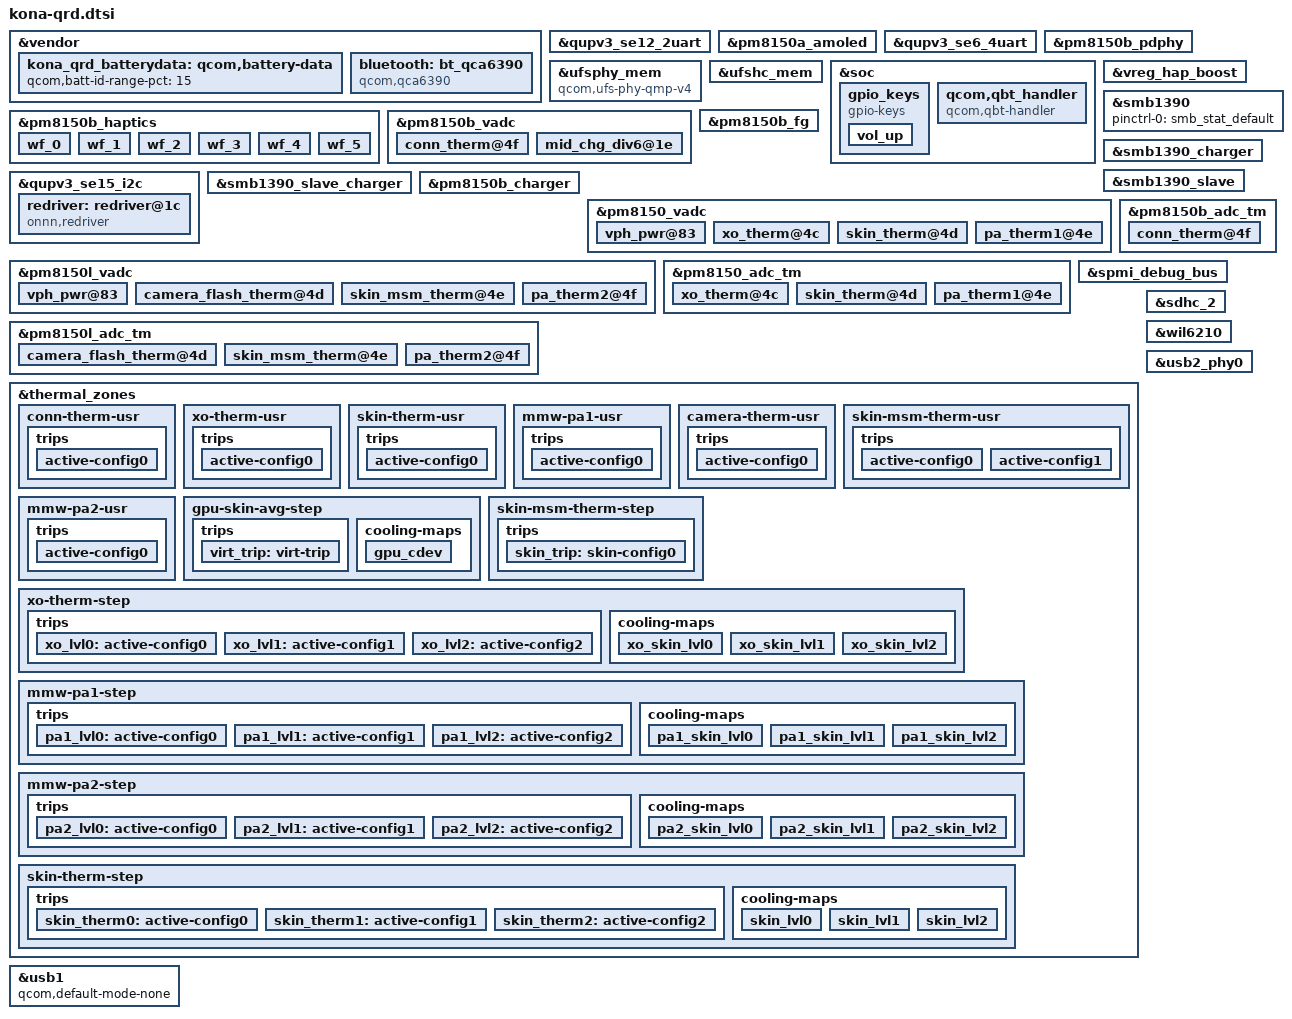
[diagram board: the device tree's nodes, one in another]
#include <dt-bindings/gpio/gpio.h>
#include "kona-pmic-overlay.dtsi"
#include "kona-thermal-overlay.dtsi"
#include "kona-audio-overlay.dtsi"
#include <dt-bindings/iio/qti_power_supply_iio.h>
#include "display/kona-sde.dtsi"
#include "display/kona-sde-display.dtsi"

&vendor {
	kona_qrd_batterydata: qcom,battery-data {
		qcom,batt-id-range-pct = <15>;
	};
};

&qupv3_se12_2uart {
	status = "okay";
};

&pm8150a_amoled {
	status = "ok";
};

&qupv3_se6_4uart {
	status = "ok";
};

&pm8150b_pdphy {
	#io-channel-cells = <1>;
	io-channels = <&pm8150b_charger PSY_IIO_PD_ACTIVE>,
		      <&pm8150b_charger PSY_IIO_TYPEC_CC_ORIENTATION>,
		      <&pm8150b_charger PSY_IIO_CONNECTOR_TYPE>,
		      <&pm8150b_charger PSY_IIO_TYPEC_POWER_ROLE>,
		      <&pm8150b_charger PSY_IIO_PD_USB_SUSPEND_SUPPORTED>,
		      <&pm8150b_charger PSY_IIO_TYPEC_SRC_RP>,
		      <&pm8150b_charger PSY_IIO_PD_IN_HARD_RESET>,
		      <&pm8150b_charger PSY_IIO_PD_CURRENT_MAX>,
		      <&pm8150b_charger PSY_IIO_PR_SWAP>,
		      <&pm8150b_charger PSY_IIO_PD_VOLTAGE_MIN>,
		      <&pm8150b_charger PSY_IIO_PD_VOLTAGE_MAX>,
		      <&pm8150b_charger PSY_IIO_USB_REAL_TYPE>,
		      <&pm8150b_charger PSY_IIO_TYPEC_MODE>,
		      <&pm8150b_charger PSY_IIO_PE_START>;
	io-channel-names = "pd_active",
			   "typec_cc_orientation",
			   "connector_type",
			   "typec_power_role",
			   "pd_usb_suspend_supported",
			   "typec_src_rp",
			   "pd_in_hard_reset",
			   "pr_current_max",
			   "pr_swap",
			   "pd_voltage_min",
			   "pd_voltage_max",
			   "real_type",
			   "typec_mode",
			   "pe_start";
};

&ufsphy_mem {
	compatible = "qcom,ufs-phy-qmp-v4";

	vdda-phy-supply = <&pm8150_l5>;
	vdda-phy-always-on;
	vdda-pll-supply = <&pm8150_l9>;
	vdda-phy-max-microamp = <89900>;
	vdda-pll-max-microamp = <18800>;

	status = "ok";
};

&ufshc_mem {
	limit-tx-hs-gear = <3>;
	limit-rx-hs-gear = <3>;
	limit-rate = <1>; /* HS Rate-A */
	vdd-hba-supply = <&ufs_phy_gdsc>;
	vdd-hba-fixed-regulator;
	vcc-supply = <&pm8150_l17>;
	vcc-voltage-level = <2504000 2950000>;
	vcc-low-voltage-sup;
	vccq-supply = <&pm8150_l6>;
	vccq2-supply = <&pm8150_s4>;
	vcc-max-microamp = <800000>;
	vccq-max-microamp = <800000>;
	vccq2-max-microamp = <800000>;

	qcom,vddp-ref-clk-supply = <&pm8150_l6>;
	qcom,vddp-ref-clk-max-microamp = <100>;
	qcom,vccq-parent-supply = <&pm8150a_s8>;
	qcom,vccq-parent-max-microamp = <210000>;

	status = "ok";
};

&soc {
	gpio_keys {
		compatible = "gpio-keys";
		label = "gpio-keys";

		pinctrl-names = "default";
		pinctrl-0 = <&key_vol_up_default>;

		vol_up {
			label = "volume_up";
			gpios = <&pm8150_gpios 6 GPIO_ACTIVE_LOW>;
			linux,input-type = <1>;
			linux,code = <KEY_VOLUMEUP>;
			gpio-key,wakeup;
			debounce-interval = <15>;
			linux,can-disable;
		};
	};

	qcom,qbt_handler {
		compatible = "qcom,qbt-handler";
		qcom,ipc-gpio = <&tlmm 23 0>;
		pinctrl-names = "default";
		pinctrl-0 = <&key_home_default>;
		qcom,finger-detect-gpio = <&pm8150_gpios 1 0>;
	};
};

&vreg_hap_boost {
	status = "ok";
};

&pm8150b_haptics {
	qcom,vmax-mv = <1697>;
	qcom,play-rate-us = <5882>;
	vdd-supply = <&vreg_hap_boost>;

	wf_0 {
		/* CLICK */
		qcom,wf-play-rate-us = <5882>;
		qcom,wf-vmax-mv = <1697>;
	};

	wf_1 {
		/* DOUBLE CLICK */
		qcom,wf-play-rate-us = <5882>;
		qcom,wf-vmax-mv = <1697>;
	};

	wf_2 {
		/* TICK */
		qcom,wf-play-rate-us = <5882>;
		qcom,wf-vmax-mv = <1697>;
	};

	wf_3 {
		/* THUD */
		qcom,wf-play-rate-us = <5882>;
		qcom,wf-vmax-mv = <1697>;
	};

	wf_4 {
		/* POP */
		qcom,wf-play-rate-us = <5882>;
		qcom,wf-vmax-mv = <1697>;
	};

	wf_5 {
		/* HEAVY CLICK */
		qcom,wf-play-rate-us = <5882>;
		qcom,wf-vmax-mv = <1697>;
	};
};

&pm8150b_vadc {
	#address-cells = <1>;
	#size-cells = <0>;

	conn_therm@4f {
		reg = <ADC5_AMUX_THM3_100K_PU>;
		label = "conn_therm";
		qcom,ratiometric;
		qcom,hw-settle-time = <200>;
		qcom,pre-scaling = <1 1>;
	};

	mid_chg_div6@1e {
		reg = <ADC5_MID_CHG_DIV6>;
		label = "mid_voltage";
		qcom,pre-scaling = <1 6>;
	};
};

&qupv3_se15_i2c {
	#address-cells = <1>;
	#size-cells = <0>;
	status = "ok";
	redriver: redriver@1c {
		compatible = "onnn,redriver";
		reg = <0x1c>;
		extcon = <&pm8150b_pdphy>, <&pm8150b_pdphy>;
		eq = /bits/ 8 <
				/* Parameters for USB */
				0x4 0x4 0x4 0x4
				/* Parameters for DP */
				0x6 0x4 0x4 0x6>;
		flat-gain = /bits/ 8 <
				/* Parameters for USB */
				0x3 0x1 0x1 0x3
				/* Parameters for DP */
				0x2 0x1 0x1 0x2>;
		output-comp = /bits/ 8 <
				/* Parameters for USB */
				0x3 0x3 0x3 0x3
				/* Parameters for DP */
				0x3 0x3 0x3 0x3>;
		loss-match = /bits/ 8 <
				/* Parameters for USB */
				0x1 0x3 0x3 0x1
				/* Parameters for DP */
				0x3 0x3 0x3 0x3>;
	};


	#include "smb1390.dtsi"
};

&smb1390 {
	pinctrl-names = "default";
	pinctrl-0 = <&smb_stat_default>;
	status = "ok";
};

&smb1390_charger {
	io-channels = <&pm8150b_vadc ADC5_AMUX_THM2>;
	io-channel-names = "cp_die_temp";
	qcom,parallel-output-mode = <2>;
	qcom,min-ilim-ua = <750000>;
	qcom,parallel-input-mode = <1>;
	status = "ok";
};

&smb1390_slave {
	status = "ok";
};

&smb1390_slave_charger {
	status = "ok";
};

&pm8150b_charger {
	status = "ok";
	#io-channel-cells = <1>;
	qcom,sec-charger-config = <1>;
	qcom,auto-recharge-soc = <98>;
	io-channels = <&pm8150b_vadc ADC5_USB_IN_V_16>,
		      <&pm8150b_vadc ADC5_USB_IN_I>,
		      <&pm8150b_vadc ADC5_SBUx>,
		      <&pm8150b_vadc ADC5_VPH_PWR>,
		      <&pm8150b_vadc ADC5_DIE_TEMP>,
		      <&pm8150b_vadc ADC5_MID_CHG_DIV6>,
		      <&pm8150b_vadc ADC5_CHG_TEMP>;
	io-channel-names = "usb_in_voltage",
			   "usb_in_current",
			   "sbux_res",
			   "vph_voltage",
			   "die_temp",
			   "mid_voltage",
			   "chg_temp";
	qcom,battery-data = <&kona_qrd_batterydata>;
	qcom,sw-jeita-enable;
	qcom,wd-bark-time-secs = <16>;
	qcom,suspend-input-on-debug-batt;
	qcom,fcc-stepping-enable;
	qcom,smb-internal-pull-kohm = <0>;
	qcom,thermal-mitigation = <5325000 4500000 4000000 3500000 3000000
				2500000 2000000 1500000 1000000 500000>;
};

&pm8150b_fg {
	status = "ok";
	qcom,battery-data = <&kona_qrd_batterydata>;
	qcom,hold-soc-while-full;
	qcom,linearize-soc;
	qcom,five-pin-battery;
	qcom,cl-wt-enable;
	qcom,soc-scale-mode-en;
	/* ESR fast calibration */
	qcom,fg-esr-timer-chg-fast = <0 7>;
	qcom,fg-esr-timer-dischg-fast = <0 7>;
	qcom,fg-esr-timer-chg-slow = <0 96>;
	qcom,fg-esr-timer-dischg-slow = <0 96>;
	qcom,fg-esr-cal-soc-thresh = <26 230>;
	qcom,fg-esr-cal-temp-thresh = <10 40>;
};

&pm8150_vadc {
	#address-cells = <1>;
	#size-cells = <0>;

	vph_pwr@83 {
		reg = <ADC5_VPH_PWR>;
		label = "vph_pwr";
		qcom,pre-scaling = <1 3>;
	};

	xo_therm@4c {
		reg = <ADC5_XO_THERM_100K_PU>;
		label = "xo_therm";
		qcom,ratiometric;
		qcom,hw-settle-time = <200>;
		qcom,pre-scaling = <1 1>;
	};

	skin_therm@4d {
		reg = <ADC5_AMUX_THM1_100K_PU>;
		label = "skin_therm";
		qcom,ratiometric;
		qcom,hw-settle-time = <200>;
		qcom,pre-scaling = <1 1>;
	};

	pa_therm1@4e {
		reg = <ADC5_AMUX_THM2_100K_PU>;
		label = "pa_therm1";
		qcom,ratiometric;
		qcom,hw-settle-time = <200>;
		qcom,pre-scaling = <1 1>;
	};
};

&pm8150l_vadc {
	#address-cells = <1>;
	#size-cells = <0>;

	vph_pwr@83 {
		reg = <ADC5_VPH_PWR>;
		label = "vph_pwr";
		qcom,pre-scaling = <1 3>;
	};

	camera_flash_therm@4d {
		reg = <ADC5_AMUX_THM1_100K_PU>;
		label = "camera_flash_therm";
		qcom,ratiometric;
		qcom,hw-settle-time = <200>;
		qcom,pre-scaling = <1 1>;
	};

	skin_msm_therm@4e {
		reg = <ADC5_AMUX_THM2_100K_PU>;
		label = "skin_msm_therm";
		qcom,ratiometric;
		qcom,hw-settle-time = <200>;
		qcom,pre-scaling = <1 1>;
	};

	pa_therm2@4f {
		reg = <ADC5_AMUX_THM3_100K_PU>;
		label = "pa_therm2";
		qcom,ratiometric;
		qcom,hw-settle-time = <200>;
		qcom,pre-scaling = <1 1>;
	};
};

&pm8150b_adc_tm {
	#address-cells = <1>;
	#size-cells = <0>;

	io-channels = <&pm8150b_vadc ADC5_AMUX_THM3_100K_PU>;

	conn_therm@4f {
		reg = <ADC5_AMUX_THM3_100K_PU>;
		qcom,ratiometric;
		qcom,hw-settle-time = <200>;
	};
};

&pm8150_adc_tm {
	#address-cells = <1>;
	#size-cells = <0>;

	io-channels = <&pm8150_vadc ADC5_XO_THERM_100K_PU>,
			<&pm8150_vadc ADC5_AMUX_THM1_100K_PU>,
			<&pm8150_vadc ADC5_AMUX_THM2_100K_PU>;

	xo_therm@4c {
		reg = <ADC5_XO_THERM_100K_PU>;
		qcom,ratiometric;
		qcom,hw-settle-time = <200>;
	};

	skin_therm@4d {
		reg = <ADC5_AMUX_THM1_100K_PU>;
		qcom,ratiometric;
		qcom,hw-settle-time = <200>;
	};

	pa_therm1@4e {
		reg = <ADC5_AMUX_THM2_100K_PU>;
		qcom,ratiometric;
		qcom,hw-settle-time = <200>;
	};
};

&pm8150l_adc_tm {
	#address-cells = <1>;
	#size-cells = <0>;

	camera_flash_therm@4d {
		reg = <ADC5_AMUX_THM1_100K_PU>;
		qcom,ratiometric;
		qcom,hw-settle-time = <200>;
	};

	skin_msm_therm@4e {
		reg = <ADC5_AMUX_THM2_100K_PU>;
		qcom,ratiometric;
		qcom,hw-settle-time = <200>;
	};

	pa_therm2@4f {
		reg = <ADC5_AMUX_THM3_100K_PU>;
		qcom,ratiometric;
		qcom,hw-settle-time = <200>;
	};
};

&spmi_debug_bus {
	status = "ok";
};

&thermal_zones {
	conn-therm-usr {
		polling-delay-passive = <0>;
		polling-delay = <0>;
		thermal-governor = "user_space";
		thermal-sensors = <&pm8150b_adc_tm ADC5_AMUX_THM3_100K_PU>;
		wake-capable-sensor;
		trips {
			active-config0 {
				temperature = <125000>;
				hysteresis = <1000>;
				type = "passive";
			};
		};
	};

	xo-therm-usr {
		polling-delay-passive = <0>;
		polling-delay = <0>;
		thermal-governor = "user_space";
		thermal-sensors = <&pm8150_adc_tm ADC5_XO_THERM_100K_PU>;
		wake-capable-sensor;
		trips {
			active-config0 {
				temperature = <125000>;
				hysteresis = <1000>;
				type = "passive";
			};
		};
	};

	skin-therm-usr {
		polling-delay-passive = <0>;
		polling-delay = <0>;
		thermal-governor = "user_space";
		thermal-sensors = <&pm8150_adc_tm ADC5_AMUX_THM1_100K_PU>;
		wake-capable-sensor;
		trips {
			active-config0 {
				temperature = <125000>;
				hysteresis = <1000>;
				type = "passive";
			};
		};
	};

	mmw-pa1-usr {
		polling-delay-passive = <0>;
		polling-delay = <0>;
		thermal-governor = "user_space";
		thermal-sensors = <&pm8150_adc_tm ADC5_AMUX_THM2_100K_PU>;
		wake-capable-sensor;
		trips {
			active-config0 {
				temperature = <125000>;
				hysteresis = <1000>;
				type = "passive";
			};
		};
	};

	camera-therm-usr {
		polling-delay-passive = <0>;
		polling-delay = <0>;
		thermal-governor = "user_space";
		thermal-sensors = <&pm8150l_adc_tm ADC5_AMUX_THM1_100K_PU>;
		wake-capable-sensor;
		trips {
			active-config0 {
				temperature = <125000>;
				hysteresis = <1000>;
				type = "passive";
			};
		};
	};

	skin-msm-therm-usr {
		polling-delay-passive = <0>;
		polling-delay = <0>;
		thermal-governor = "user_space";
		thermal-sensors = <&pm8150l_adc_tm ADC5_AMUX_THM2_100K_PU>;
		wake-capable-sensor;
		trips {
			active-config0 {
				temperature = <125000>;
				hysteresis = <1000>;
				type = "passive";
			};

			active-config1 {
				temperature = <125000>;
				hysteresis = <1000>;
				type = "passive";
			};
		};
	};

	mmw-pa2-usr {
		polling-delay-passive = <0>;
		polling-delay = <0>;
		thermal-governor = "user_space";
		thermal-sensors = <&pm8150l_adc_tm ADC5_AMUX_THM3_100K_PU>;
		wake-capable-sensor;
		trips {
			active-config0 {
				temperature = <125000>;
				hysteresis = <1000>;
				type = "passive";
			};
		};
	};

	gpu-skin-avg-step {
		polling-delay-passive = <1000>;
		polling-delay = <5000>;
		thermal-governor = "step_wise";
		trips {
			virt_trip: virt-trip {
				temperature = <64600>;
				hysteresis = <2000>;
				type = "passive";
			};
		};

		cooling-maps {
			gpu_cdev {
				trip = <&virt_trip>;
				cooling-device = <&msm_gpu 0 1>;
			};
		};
	};

	skin-msm-therm-step {
		polling-delay-passive = <0>;
		polling-delay = <0>;
		thermal-governor = "step_wise";
		thermal-sensors = <&pm8150l_adc_tm ADC5_AMUX_THM2_100K_PU>;
		wake-capable-sensor;
		trips {
			skin_trip: skin-config0 {
				temperature = <46000>;
				hysteresis = <0>;
				type = "passive";
			};
		};
	};

	xo-therm-step {
		polling-delay-passive = <0>;
		polling-delay = <0>;
		thermal-governor = "step_wise";
		thermal-sensors = <&pm8150_adc_tm ADC5_XO_THERM_100K_PU>;

		trips {
			xo_lvl0: active-config0 {
				temperature = <42000>;
				hysteresis = <2000>;
				type = "passive";
			};

			xo_lvl1: active-config1 {
				temperature = <46000>;
				hysteresis = <2000>;
				type = "passive";
			};

			xo_lvl2: active-config2 {
				temperature = <56000>;
				hysteresis = <6000>;
				type = "passive";
			};
		};

		cooling-maps {
			xo_skin_lvl0 {
				trip = <&xo_lvl0>;
				cooling-device = <&modem_mmw_skin2 1 1>;
			};

			xo_skin_lvl1 {
				trip = <&xo_lvl1>;
				cooling-device = <&modem_mmw_skin2 2 2>;
			};

			xo_skin_lvl2 {
				trip = <&xo_lvl2>;
				cooling-device = <&modem_mmw_skin2 3 3>;
			};
		};
	};

	mmw-pa1-step {
		polling-delay-passive = <0>;
		polling-delay = <0>;
		thermal-governor = "step_wise";
		thermal-sensors = <&pm8150_adc_tm ADC5_AMUX_THM2_100K_PU>;

		trips {
			pa1_lvl0: active-config0 {
				temperature = <44000>;
				hysteresis = <5000>;
				type = "passive";
			};

			pa1_lvl1: active-config1 {
				temperature = <48000>;
				hysteresis = <2000>;
				type = "passive";
			};

			pa1_lvl2: active-config2 {
				temperature = <56000>;
				hysteresis = <6000>;
				type = "passive";
			};
		};

		cooling-maps {
			pa1_skin_lvl0 {
				trip = <&pa1_lvl0>;
				cooling-device = <&modem_mmw_skin0 1 1>;
			};

			pa1_skin_lvl1 {
				trip = <&pa1_lvl1>;
				cooling-device = <&modem_mmw_skin0 2 2>;
			};

			pa1_skin_lvl2 {
				trip = <&pa1_lvl2>;
				cooling-device = <&modem_mmw_skin0 3 3>;
			};
		};
	};

	mmw-pa2-step {
		polling-delay-passive = <0>;
		polling-delay = <0>;
		thermal-governor = "step_wise";
		thermal-sensors = <&pm8150l_adc_tm ADC5_AMUX_THM3_100K_PU>;

		trips {
			pa2_lvl0: active-config0 {
				temperature = <42000>;
				hysteresis = <4000>;
				type = "passive";
			};

			pa2_lvl1: active-config1 {
				temperature = <46000>;
				hysteresis = <2000>;
				type = "passive";
			};

			pa2_lvl2: active-config2 {
				temperature = <56000>;
				hysteresis = <6000>;
				type = "passive";
			};
		};

		cooling-maps {
			pa2_skin_lvl0 {
				trip = <&pa2_lvl0>;
				cooling-device = <&modem_mmw_skin1 1 1>;
			};

			pa2_skin_lvl1 {
				trip = <&pa2_lvl1>;
				cooling-device = <&modem_mmw_skin1 2 2>;
			};

			pa2_skin_lvl2 {
				trip = <&pa2_lvl2>;
				cooling-device = <&modem_mmw_skin1 3 3>;
			};
		};
	};

	skin-therm-step {
		polling-delay-passive = <0>;
		polling-delay = <0>;
		thermal-governor = "step_wise";
		thermal-sensors = <&pm8150_adc_tm ADC5_AMUX_THM1_100K_PU>;
		wake-capable-sensor;
		disable-thermal-zone;

		trips {
			skin_therm0: active-config0 {
				temperature = <62000>;
				hysteresis = <5000>;
				type = "passive";
			};

			skin_therm1: active-config1 {
				temperature = <65000>;
				hysteresis = <5000>;
				type = "passive";
			};

			skin_therm2: active-config2 {
				temperature = <72000>;
				hysteresis = <2000>;
				type = "passive";
			};
		};

		cooling-maps {
			skin_lvl0 {
				trip = <&skin_therm0>;
				cooling-device = <&modem_skin 1 1>;
			};

			skin_lvl1 {
				trip = <&skin_therm1>;
				cooling-device = <&modem_skin 2 2>;
			};

			skin_lvl2 {
				trip = <&skin_therm2>;
				cooling-device = <&modem_skin 3 3>;
			};
		};

	};
};

&sdhc_2 {
	vdd-supply = <&L9C>;
	qcom,vdd-voltage-level = <2950000 2960000>;
	qcom,vdd-current-level = <200 800000>;

	vdd-io-supply = <&L6C>;
	qcom,vdd-io-voltage-level = <1808000 2960000>;
	qcom,vdd-io-current-level = <200 22000>;

	pinctrl-names = "default", "sleep";
	pinctrl-0 = <&sdc2_on>;
	pinctrl-1 = <&sdc2_off>;

	cd-gpios = <&tlmm 77 GPIO_ACTIVE_LOW>;

	status = "ok";
};

&vendor {
	bluetooth: bt_qca6390 {
		compatible = "qcom,qca6390";
		pinctrl-names = "default";
		pinctrl-0 = <&bt_en_sleep>;
		qcom,bt-reset-gpio = <&tlmm 21 0>; /* BT_EN */
		qcom,bt-sw-ctrl-gpio = <&tlmm 124 0>; /* SW_CTRL */
		qcom,bt-vdd-aon-supply = <&pm8150_s6>;
		qcom,bt-vdd-dig-supply = <&pm8009_s2>;
		qcom,bt-vdd-rfa1-supply = <&pm8150_s5>;
		qcom,bt-vdd-rfa2-supply = <&pm8150a_s8>;
		qcom,bt-vdd-asd-supply = <&pm8150_l16>;

		qcom,bt-vdd-aon-config = <950000 950000 0 1>;
		qcom,bt-vdd-dig-config = <950000 952000 0 1>;
		qcom,bt-vdd-rfa1-config = <1900000 1900000 0 1>;
		qcom,bt-vdd-rfa2-config = <1350000 1350000 0 1>;
		qcom,bt-vdd-asd-config = <3024000 3304000 10000 1>;

	};
};

&usb1 {
	status = "ok";
	qcom,default-mode-none;
};

&wil6210 {
	status = "ok";
};

&usb2_phy0 {
	qcom,param-override-seq =
		<0xc7 0x6c
		0x0f 0x70
		0x03 0x74>;
};
